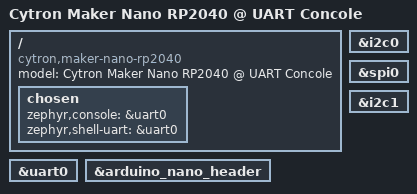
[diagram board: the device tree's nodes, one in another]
/*
 * Copyright (c) 2023 TiaC Systems
 * SPDX-License-Identifier: Apache-2.0
 */

/dts-v1/;

/ {
	model = "Cytron Maker Nano RP2040 @ UART Concole";
	compatible = "cytron,maker-nano-rp2040", "cytron,maker-nano-rp2040-uartcons";

	chosen {
		zephyr,console = &uart0;
		zephyr,shell-uart = &uart0;
	};
};

#include "cytron_rp2040-makernano.dtsi"
#include "cytron_rp2040-2mb.dtsi"

#include "maker_buzzer.dtsi"

#include "makernano_button.dtsi"
#include "makernano_led_mono.dtsi"
#include "makernano_led_ws2812.dtsi"
#include "makernano_r3_connector.dtsi"

arduino_nano_i2c: &i2c0 {};
arduino_nano_spi: &spi0 {};
arduino_nano_serial: &uart0 {};
arduino_nano_gpio: &arduino_nano_header {};

#include "makernano_grove_connectors.dtsi"

grove_serial: &uart0 {};
grove_i2c: &i2c1 {};

#include "cytron_rp2040-makernano-tweaks.dtsi"
